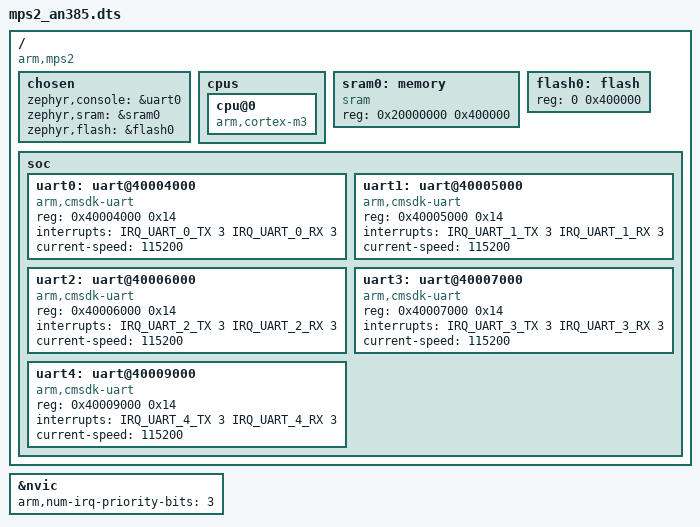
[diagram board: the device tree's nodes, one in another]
/dts-v1/;

#include <arm/armv7-m.dtsi>
#include "arm/mps2/soc_irq.h"

/ {
	compatible = "arm,mps2";
	#address-cells = <1>;
	#size-cells = <1>;

	chosen {
		zephyr,console = &uart0;
		zephyr,sram = &sram0;
		zephyr,flash = &flash0;
	};

	cpus {
		cpu@0 {
			compatible = "arm,cortex-m3";
		};
	};

	sram0: memory {
		compatible = "sram";
		reg = <0x20000000 0x400000>;
	};

	flash0: flash {
		reg = <0 0x400000>;
	};

	soc {
		uart0: uart@40004000 {
			compatible = "arm,cmsdk-uart";
			reg = <0x40004000 0x14>;
			interrupts = <IRQ_UART_0_TX 3 IRQ_UART_0_RX 3>;
			current-speed = <115200>;
		};

		uart1: uart@40005000 {
			compatible = "arm,cmsdk-uart";
			reg = <0x40005000 0x14>;
			interrupts = <IRQ_UART_1_TX 3 IRQ_UART_1_RX 3>;
			current-speed = <115200>;
		};

		uart2: uart@40006000 {
			compatible = "arm,cmsdk-uart";
			reg = <0x40006000 0x14>;
			interrupts = <IRQ_UART_2_TX 3 IRQ_UART_2_RX 3>;
			current-speed = <115200>;
		};

		uart3: uart@40007000 {
			compatible = "arm,cmsdk-uart";
			reg = <0x40007000 0x14>;
			interrupts = <IRQ_UART_3_TX 3 IRQ_UART_3_RX 3>;
			current-speed = <115200>;
		};

		uart4: uart@40009000 {
			compatible = "arm,cmsdk-uart";
			reg = <0x40009000 0x14>;
			interrupts = <IRQ_UART_4_TX 3 IRQ_UART_4_RX 3>;
			current-speed = <115200>;
		};
	};
};

&nvic {
	arm,num-irq-priority-bits = <3>;
};
